# allwinner_xr806_unofficial register map
File version: 1.2
CPU: CM33 r1p2, little endian, MPU, FPU, DSP, vendor SysTick, 8 interrupt priority bits, 8 SAU regions
Registers are 32-bit, read-write, reset 0x0 unless marked. A register's access mark holds for its fields unless they carry their own. Offsets are from the block's base; [hi:lo] are bit positions.

## TWI0
Base 0x40041C00
Same registers: TWI1 0x40042000
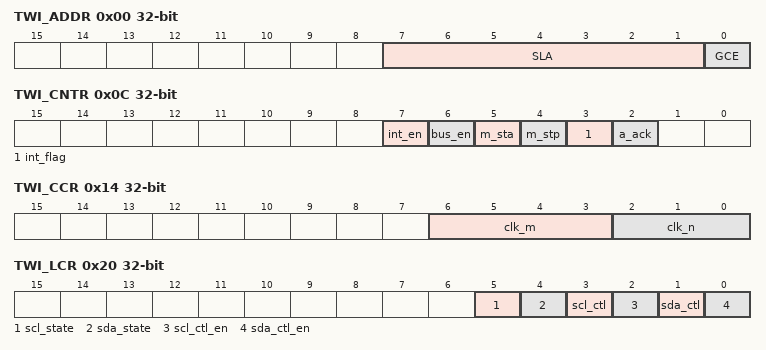
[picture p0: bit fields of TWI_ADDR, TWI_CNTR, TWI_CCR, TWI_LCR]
0x00 TWI_ADDR — TWI Slave Address Register
  [7:1] SLA — Slave Address
  [0] GCE
    0=disable; 1=enable
0x04 TWI_XADDR — TWI Extended Slave Address Register
  [7:0] SLAX — Extend Slave Address . SLAX[7:0]
0x08 TWI_DATA — TWI Data Byte Register
  [7:0] data — Data byte transmitted or received
0x0C TWI_CNTR — TWI Control Register
  [7] int_en — Interrupt Enable
    0=low (The interrupt line always low); 1=high (The interrupt line will go high when INT_FLAG is set)
  [6] bus_en — TWI Bus Enable
    0=ignored; 1=respond
  [5] m_sta — Master Mode Start
  [4] m_stp — Master Mode Stop
  [3] int_flag — Interrupt Flag
  [2] a_ack — Assert Acknowledge
0x10 TWI_STAT ro — TWI Status Register
  [7:0] sta
    0=be (Bus error); 8=sct (START condition transmitted); 16=rsct (Repeated START condition transmitted); 24=awbt_ar (Address + Write bit transmitted, ACK received); 32=awbt_anr (Address + Write bit transmitted, ACK not received); 40=dbtm_ar (Data byte transmitted in master mode, ACK received); 48=dbtm_anr (Data byte transmitted in master mode, ACK not received); 56=al_a_db (Arbitration lost in address or data byte); 64=arbt_ar (Address + Read bit transmitted, ACK received); 72=arbt_anr (Address + Read bit transmitted, ACK not received); 80=dbrm_at (Data byte received in master mode, ACK transmitted); 88=dbrm_ant (Data byte received in master mode, not ACK transmitted); 96=sawr_at (Slave address + Write bit received, ACK transmitted); 104=al_am_sawr_at (Arbitration lost in the address as master, slave address + Write bit received, ACK transmitted); 112=gcar_at (General Call address received, ACK transmitted); 120=al_am_gcar_at (Arbitration lost in the address as master, General Call address received, ACK transmitted); 128=dbr_sar_at (Data byte received after slave address received, ACK transmitted); 136=dbr_sar_ant (Data byte received after slave address received, not ACK transmitted); 144=dbr_gcr_at (Data byte received after General Call received, ACK transmitted); 152=dbr_gcr_ant (Data byte received after General Call received, not ACK transmitted); 160=srscrs (STOP or repeated START condition received in slave mode); 168=sarr_at (Slave address + Read bit received, ACK transmitted); 176=al_am_sarr_at (Arbitration lost in the address as master, slave address + Read bit received, ACK transmitted); 184=dbts_ar (Data byte transmitted in slave mode, ACK received); 192=dbts_anr (Data byte transmitted in slave mode, ACK not received); 200=lbts_ar (The Last byte transmitted in slave mode, ACK received); 208=sawt_ar (Second Address byte + Write bit transmitted, ACK received); 216=sawt_anr (Second Address byte + Write bit transmitted, ACK not received); 248=nrsi (No relevant status information, INT_FLAG=0)
0x14 TWI_CCR — TWI Clock Control Register
  [6:3] clk_m, [2:0] clk_n
0x18 TWI_SRST — TWI Software Reset Register
  [0] soft_rst — Soft Reset
0x1C TWI_EFR — TWI Enhance Feature Register
  [1:0] dbn — Data Byte Number Follow Read Command Control
    0=B0 (No data byte can be written after the read command); 1=B1 (1-byte data can be written after the read command); 2=B2 (2-byte data can be written after the read command); 3=B3 (3-byte data can be written after the read command)
0x20 TWI_LCR — TWI Line Control Register
  [5] scl_state ro — Current State of TWI_SCL
    0=low; 1=high
  [4] sda_state ro — Current State of TWI_SDA
    0=low; 1=high
  [3] scl_ctl — TWI_SCL Line State Control Bit
    0=low; 1=high
  [2] scl_ctl_en — TWI_SCL Line State Control Enable
    0=disable; 1=enable
  [1] sda_ctl — TWI_SDA Line State Control Bit
    0=low; 1=high
  [0] sda_ctl_en — TWI_SDA Line State Control Enable
    0=disable; 1=enable
